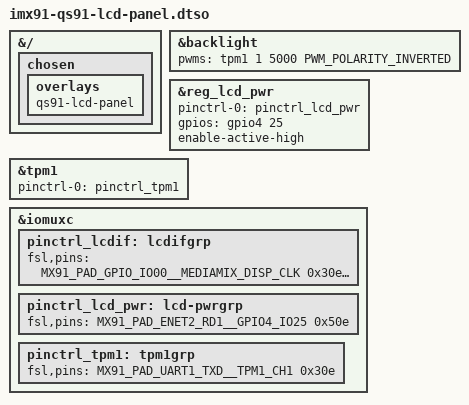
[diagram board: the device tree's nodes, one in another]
// SPDX-License-Identifier: (GPL-2.0 OR MIT)
/*
 * Copyright 2023 Lothar Waßmann <LW@KARO-electronics.de>
 *
 */

/dts-v1/;
/plugin/;

#include <dt-bindings/gpio/gpio.h>
#include <dt-bindings/pwm/pwm.h>
#include "imx91-pinfunc.h"
#include "includes/imx91-karo-backlight.dtsi"
#include "includes/imx91-karo-lcd-panel.dtsi"

&{/} {
	chosen {
		overlays {
			qs91-lcd-panel;
		};
	};
};

&backlight {
	pwms = <&tpm1 1 5000 PWM_POLARITY_INVERTED>;
};

&reg_lcd_pwr {
	pinctrl-names = "default";
	pinctrl-0 = <&pinctrl_lcd_pwr>;
	gpios = <&gpio4 25 GPIO_ACTIVE_HIGH>;
	enable-active-high;
	status = "okay";
};

&tpm1 {
	pinctrl-names = "default";
	pinctrl-0 = <&pinctrl_tpm1>;
	status = "okay";
};

&iomuxc {
	pinctrl_lcdif: lcdifgrp {
		fsl,pins = <
			MX91_PAD_GPIO_IO00__MEDIAMIX_DISP_CLK		0x30e
			MX91_PAD_GPIO_IO01__MEDIAMIX_DISP_DE		0x30e
			MX91_PAD_GPIO_IO02__MEDIAMIX_DISP_VSYNC		0x30e
			MX91_PAD_GPIO_IO03__MEDIAMIX_DISP_HSYNC		0x30e
			/* BLUE */
			MX91_PAD_GPIO_IO04__MEDIAMIX_DISP_DATA0		0x30e
			MX91_PAD_GPIO_IO05__MEDIAMIX_DISP_DATA1		0x30e
			MX91_PAD_GPIO_IO06__MEDIAMIX_DISP_DATA2		0x30e
			MX91_PAD_GPIO_IO07__MEDIAMIX_DISP_DATA3		0x30e
			MX91_PAD_GPIO_IO08__MEDIAMIX_DISP_DATA4		0x30e
			MX91_PAD_GPIO_IO09__MEDIAMIX_DISP_DATA5		0x30e
			MX91_PAD_GPIO_IO10__MEDIAMIX_DISP_DATA6		0x30e
			MX91_PAD_GPIO_IO11__MEDIAMIX_DISP_DATA7		0x30e
			/* GREEN */
			/* MEDIAMIX_DISP_DATA[89] used for LPUART8_[TR]X */
			MX91_PAD_ENET2_RD2__GPIO4_IO26			0x50e
			MX91_PAD_ENET2_RD3__GPIO4_IO27			0x50e
			MX91_PAD_GPIO_IO14__MEDIAMIX_DISP_DATA10	0x30e
			MX91_PAD_GPIO_IO15__MEDIAMIX_DISP_DATA11	0x30e
			MX91_PAD_GPIO_IO16__MEDIAMIX_DISP_DATA12	0x30e
			MX91_PAD_GPIO_IO17__MEDIAMIX_DISP_DATA13	0x30e
			MX91_PAD_GPIO_IO18__MEDIAMIX_DISP_DATA14	0x30e
			MX91_PAD_GPIO_IO19__MEDIAMIX_DISP_DATA15	0x30e
			/* RED */
			MX91_PAD_GPIO_IO20__MEDIAMIX_DISP_DATA16	0x30e
			MX91_PAD_GPIO_IO21__MEDIAMIX_DISP_DATA17	0x30e
			MX91_PAD_GPIO_IO22__MEDIAMIX_DISP_DATA18	0x30e
			MX91_PAD_GPIO_IO23__MEDIAMIX_DISP_DATA19	0x30e
			MX91_PAD_GPIO_IO24__MEDIAMIX_DISP_DATA20	0x30e
			MX91_PAD_GPIO_IO25__MEDIAMIX_DISP_DATA21	0x30e
			MX91_PAD_GPIO_IO26__MEDIAMIX_DISP_DATA22	0x30e
			MX91_PAD_GPIO_IO27__MEDIAMIX_DISP_DATA23	0x30e
		>;
	};

	pinctrl_lcd_pwr: lcd-pwrgrp {
		fsl,pins = <
			MX91_PAD_ENET2_RD1__GPIO4_IO25			0x50e
		>;
	};

	pinctrl_tpm1: tpm1grp {
		fsl,pins = <
			MX91_PAD_UART1_TXD__TPM1_CH1			0x30e
		>;
	};
};
